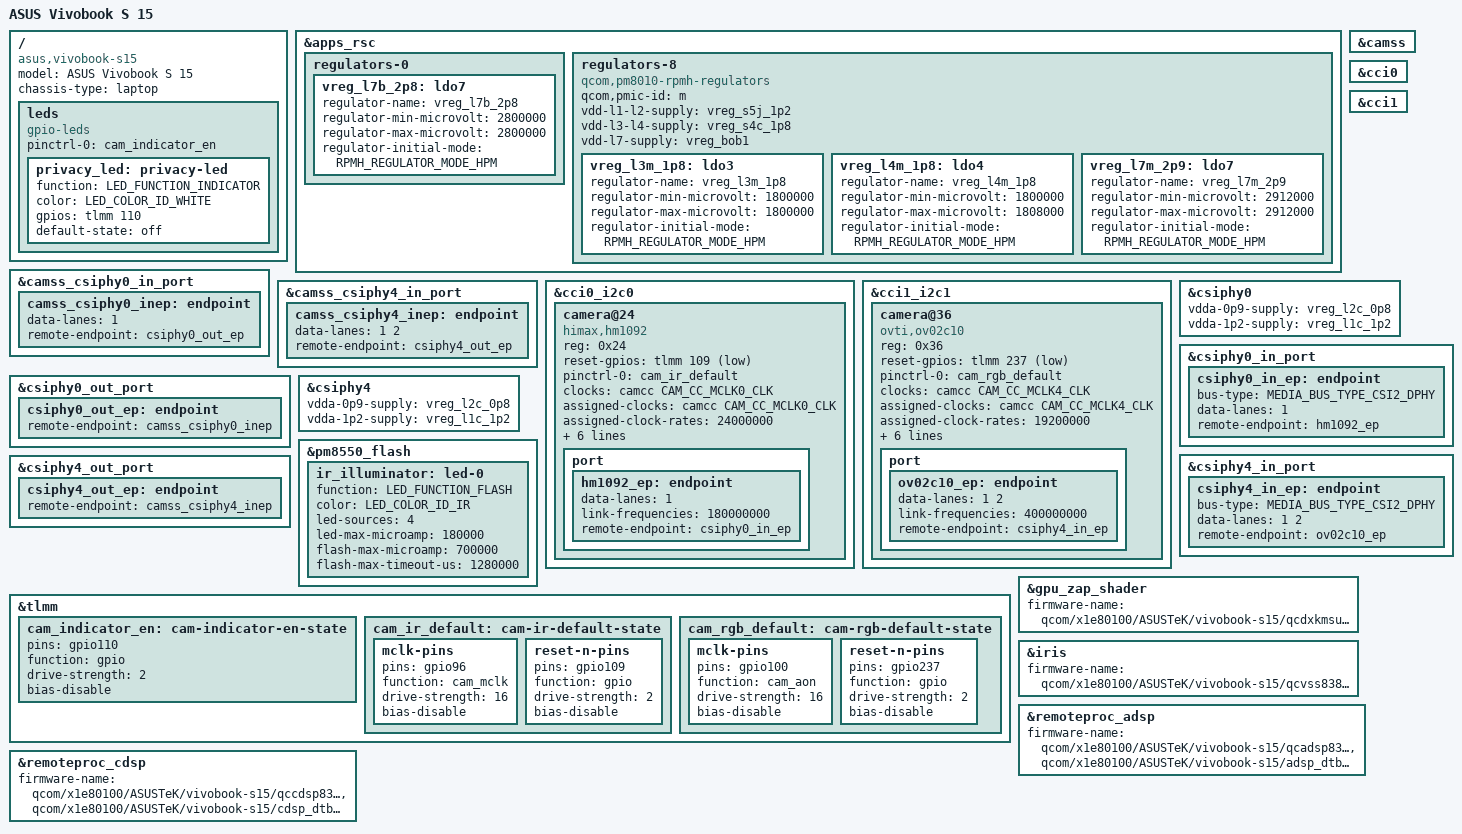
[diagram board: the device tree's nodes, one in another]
// SPDX-License-Identifier: BSD-3-Clause
/*
 * Copyright (c) 2023 Qualcomm Innovation Center, Inc. All rights reserved.
 * Copyright (c) 2024, Xilin Wu <wuxilin123@gmail.com>
 */

/dts-v1/;

#include <dt-bindings/leds/common.h>
#include <dt-bindings/media/video-interfaces.h>
#include <dt-bindings/media/video-interface-devices.h>

#include "hamoa.dtsi"
#include "x1-asus-vivobook-s15.dtsi"

/ {
	model = "ASUS Vivobook S 15";
	compatible = "asus,vivobook-s15", "qcom,x1e80100";
	chassis-type = "laptop";

	leds {
		compatible = "gpio-leds";

		pinctrl-0 = <&cam_indicator_en>;
		pinctrl-names = "default";

		privacy_led: privacy-led {
			function = LED_FUNCTION_INDICATOR;
			color = <LED_COLOR_ID_WHITE>;
			gpios = <&tlmm 110 GPIO_ACTIVE_HIGH>;
			default-state = "off";
		};
	};
};

/*
 * Cameras, from the Windows camera package (CAMF/CAMI PEP resources):
 *  - front RGB OV02C10: CCI1 bus 1 @0x36, MCLK4 19.2 MHz, reset GPIO237,
 *    AVDD L7B 2.8 V, DOVDD L3M 1.8 V, CSIPHY4 2 lanes
 *  - IR HM1092: CCI0 bus 0 @0x24, MCLK0 24 MHz, reset GPIO109,
 *    AVDD/DVDD L7M 2.912 V, DOVDD L4M 1.8 V, CSIPHY0 1 lane,
 *    illuminator on PM8550 flash channel 4
 * Same layout as the Zenbook A14.
 */
&apps_rsc {
	regulators-0 {
		vreg_l7b_2p8: ldo7 {
			regulator-name = "vreg_l7b_2p8";
			regulator-min-microvolt = <2800000>;
			regulator-max-microvolt = <2800000>;
			regulator-initial-mode = <RPMH_REGULATOR_MODE_HPM>;
		};
	};

	regulators-8 {
		compatible = "qcom,pm8010-rpmh-regulators";
		qcom,pmic-id = "m";

		vdd-l1-l2-supply = <&vreg_s5j_1p2>;
		vdd-l3-l4-supply = <&vreg_s4c_1p8>;
		vdd-l7-supply = <&vreg_bob1>;

		vreg_l3m_1p8: ldo3 {
			regulator-name = "vreg_l3m_1p8";
			regulator-min-microvolt = <1800000>;
			regulator-max-microvolt = <1800000>;
			regulator-initial-mode = <RPMH_REGULATOR_MODE_HPM>;
		};

		vreg_l4m_1p8: ldo4 {
			regulator-name = "vreg_l4m_1p8";
			regulator-min-microvolt = <1800000>;
			regulator-max-microvolt = <1808000>;
			regulator-initial-mode = <RPMH_REGULATOR_MODE_HPM>;
		};

		vreg_l7m_2p9: ldo7 {
			regulator-name = "vreg_l7m_2p9";
			regulator-min-microvolt = <2912000>;
			regulator-max-microvolt = <2912000>;
			regulator-initial-mode = <RPMH_REGULATOR_MODE_HPM>;
		};
	};
};

&camss {
	status = "okay";
};

&camss_csiphy0_in_port {
	camss_csiphy0_inep: endpoint {
		data-lanes = <1>;
		remote-endpoint = <&csiphy0_out_ep>;
	};
};

&camss_csiphy4_in_port {
	camss_csiphy4_inep: endpoint {
		data-lanes = <1 2>;
		remote-endpoint = <&csiphy4_out_ep>;
	};
};

&cci0 {
	status = "okay";
};

&cci0_i2c0 {
	camera@24 {
		compatible = "himax,hm1092";
		reg = <0x24>;

		reset-gpios = <&tlmm 109 GPIO_ACTIVE_LOW>;
		pinctrl-0 = <&cam_ir_default>;
		pinctrl-names = "default";

		clocks = <&camcc CAM_CC_MCLK0_CLK>;
		assigned-clocks = <&camcc CAM_CC_MCLK0_CLK>;
		assigned-clock-rates = <24000000>;

		orientation = <MEDIA_ORIENTATION_FRONT>;

		leds = <&privacy_led>, <&ir_illuminator>;
		led-names = "privacy", "illuminator";

		avdd-supply = <&vreg_l7m_2p9>;
		dvdd-supply = <&vreg_l7m_2p9>;
		dovdd-supply = <&vreg_l4m_1p8>;

		port {
			hm1092_ep: endpoint {
				data-lanes = <1>;
				link-frequencies = /bits/ 64 <180000000>;
				remote-endpoint = <&csiphy0_in_ep>;
			};
		};
	};
};

&cci1 {
	status = "okay";
};

&cci1_i2c1 {
	camera@36 {
		compatible = "ovti,ov02c10";
		reg = <0x36>;

		reset-gpios = <&tlmm 237 GPIO_ACTIVE_LOW>;
		pinctrl-0 = <&cam_rgb_default>;
		pinctrl-names = "default";

		clocks = <&camcc CAM_CC_MCLK4_CLK>;
		assigned-clocks = <&camcc CAM_CC_MCLK4_CLK>;
		assigned-clock-rates = <19200000>;

		orientation = <MEDIA_ORIENTATION_FRONT>;
		/* mounted upside down */
		rotation = <180>;

		leds = <&privacy_led>;
		led-names = "privacy";

		/* Windows votes no 1.2 V rail for this module */
		avdd-supply = <&vreg_l7b_2p8>;
		dovdd-supply = <&vreg_l3m_1p8>;

		port {
			ov02c10_ep: endpoint {
				data-lanes = <1 2>;
				link-frequencies = /bits/ 64 <400000000>;
				remote-endpoint = <&csiphy4_in_ep>;
			};
		};
	};
};

&csiphy0 {
	vdda-0p9-supply = <&vreg_l2c_0p8>;
	vdda-1p2-supply = <&vreg_l1c_1p2>;

	status = "okay";
};

&csiphy0_in_port {
	csiphy0_in_ep: endpoint {
		bus-type = <MEDIA_BUS_TYPE_CSI2_DPHY>;
		data-lanes = <1>;
		remote-endpoint = <&hm1092_ep>;
	};
};

&csiphy0_out_port {
	csiphy0_out_ep: endpoint {
		remote-endpoint = <&camss_csiphy0_inep>;
	};
};

&csiphy4 {
	vdda-0p9-supply = <&vreg_l2c_0p8>;
	vdda-1p2-supply = <&vreg_l1c_1p2>;

	status = "okay";
};

&csiphy4_in_port {
	csiphy4_in_ep: endpoint {
		bus-type = <MEDIA_BUS_TYPE_CSI2_DPHY>;
		data-lanes = <1 2>;
		remote-endpoint = <&ov02c10_ep>;
	};
};

&csiphy4_out_port {
	csiphy4_out_ep: endpoint {
		remote-endpoint = <&camss_csiphy4_inep>;
	};
};

&pm8550_flash {
	status = "okay";

	/* IR illuminator; Windows runs it at 700 mA flash, here only torch mode is used */
	ir_illuminator: led-0 {
		function = LED_FUNCTION_FLASH;
		color = <LED_COLOR_ID_IR>;
		led-sources = <4>;
		led-max-microamp = <180000>;
		flash-max-microamp = <700000>;
		flash-max-timeout-us = <1280000>;
	};
};

&tlmm {
	cam_indicator_en: cam-indicator-en-state {
		pins = "gpio110";
		function = "gpio";
		drive-strength = <2>;
		bias-disable;
	};

	cam_ir_default: cam-ir-default-state {
		mclk-pins {
			pins = "gpio96";
			function = "cam_mclk";
			drive-strength = <16>;
			bias-disable;
		};

		reset-n-pins {
			pins = "gpio109";
			function = "gpio";
			drive-strength = <2>;
			bias-disable;
		};
	};

	cam_rgb_default: cam-rgb-default-state {
		mclk-pins {
			pins = "gpio100";
			function = "cam_aon";
			drive-strength = <16>;
			bias-disable;
		};

		reset-n-pins {
			pins = "gpio237";
			function = "gpio";
			drive-strength = <2>;
			bias-disable;
		};
	};
};

&gpu_zap_shader {
	firmware-name = "qcom/x1e80100/ASUSTeK/vivobook-s15/qcdxkmsuc8380.mbn";
};

&iris {
	firmware-name = "qcom/x1e80100/ASUSTeK/vivobook-s15/qcvss8380.mbn";

	status = "okay";
};

&remoteproc_adsp {
	firmware-name = "qcom/x1e80100/ASUSTeK/vivobook-s15/qcadsp8380.mbn",
			"qcom/x1e80100/ASUSTeK/vivobook-s15/adsp_dtbs.elf";

	status = "okay";
};

&remoteproc_cdsp {
	firmware-name = "qcom/x1e80100/ASUSTeK/vivobook-s15/qccdsp8380.mbn",
			"qcom/x1e80100/ASUSTeK/vivobook-s15/cdsp_dtbs.elf";

	status = "okay";
};

